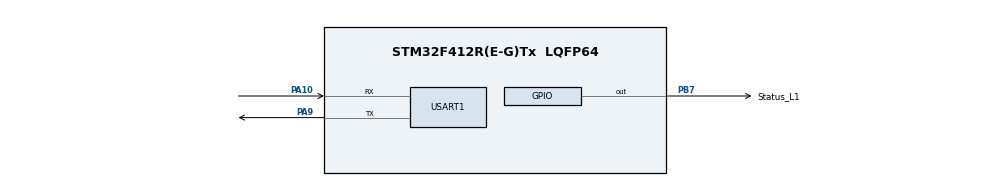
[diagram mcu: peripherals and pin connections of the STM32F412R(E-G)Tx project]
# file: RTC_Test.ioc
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Mcu.Family=STM32F4
Mcu.Name=STM32F412R(E-G)Tx
Mcu.Package=LQFP64
NVIC.PriorityGroup=NVIC_PRIORITYGROUP_4
PA10.Mode=Asynchronous
PA10.Signal=USART1_RX
PA13.Mode=Serial_Wire
PA13.Signal=SYS_JTMS-SWDIO
PA14.Mode=Serial_Wire
PA14.Signal=SYS_JTCK-SWCLK
PA9.Mode=Asynchronous
PA9.Signal=USART1_TX
PB7.GPIO_Label=Status_L1
PB7.Signal=GPIO_Output
PC14-OSC32_IN.Mode=LSE-External-Oscillator
PC14-OSC32_IN.Signal=RCC_OSC32_IN
PC15-OSC32_OUT.Mode=LSE-External-Oscillator
PC15-OSC32_OUT.Signal=RCC_OSC32_OUT
PH0\ -\ OSC_IN.Mode=HSE-External-Oscillator
PH0\ -\ OSC_IN.Signal=RCC_OSC_IN
PH1\ -\ OSC_OUT.Mode=HSE-External-Oscillator
PH1\ -\ OSC_OUT.Signal=RCC_OSC_OUT
ProjectManager.HeapSize=0x200
ProjectManager.StackSize=0x400
ProjectManager.TargetToolchain=STM32CubeIDE
RCC.CortexFreq_Value=16000000
RCC.HSE_VALUE=16000000
RCC.PLLSourceVirtual=RCC_PLLSOURCE_HSE
RCC.RCC_RTC_Clock_Source=RCC_RTCCLKSOURCE_LSE
RCC.SYSCLKSource=RCC_SYSCLKSOURCE_HSE
RCC.USBFreq_Value=96000000
RCC.VCOOutputFreq_Value=192000000
USART1.VirtualMode=VM_ASYNC
VP_RTC_VS_RTC_Activate.Mode=RTC_Enabled
board=custom

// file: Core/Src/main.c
/* USER CODE BEGIN Header */
/**
  ******************************************************************************
  * @file           : main.c
  * @brief          : Main program body
  ******************************************************************************
  * @attention
  *
  * Copyright (c) 2023 STMicroelectronics.
  * All rights reserved.
  *
  * This software is licensed under terms that can be found in the LICENSE file
  * in the root directory of this software component.
  * If no LICENSE file comes with this software, it is provided AS-IS.
  *
  ******************************************************************************
  */
/* USER CODE END Header */
#include "main.h"

/* USER CODE BEGIN Includes */
#include <string.h>
/* USER CODE END Includes */

RTC_HandleTypeDef hrtc;

UART_HandleTypeDef huart1;

void SystemClock_Config(void);
static void MX_GPIO_Init(void);
static void MX_RTC_Init(void);
static void MX_USART1_UART_Init(void);

/* USER CODE BEGIN 0 */

RTC_TimeTypeDef RTC_Time;
RTC_DateTypeDef RTC_Date;
/* USER CODE END 0 */

int main(void)
{

  /* MCU Configuration--------------------------------------------------------*/

  /* Reset of all peripherals, Initializes the Flash interface and the Systick. */
  HAL_Init();

  /* Configure the system clock */
  SystemClock_Config();

  /* Initialize all configured peripherals */
  MX_GPIO_Init();
  MX_RTC_Init();
  MX_USART1_UART_Init();
  /* USER CODE BEGIN 2 */
  HAL_RTC_Init(&hrtc);
  char DTString[1024];
  /* USER CODE END 2 */

  /* Infinite loop */
  while (1)
  {
	  HAL_RTC_GetTime(&hrtc, &RTC_Time, RTC_FORMAT_BIN);
	  HAL_RTC_GetDate(&hrtc, &RTC_Date, RTC_FORMAT_BIN);

	  sprintf(DTString,"Date: %02d.%02d.%02d  Time: %02d.%02d.%02d\n",RTC_Date.Date,RTC_Date.Month,RTC_Date.Year,RTC_Time.Hours,RTC_Time.Minutes,RTC_Time.Seconds);

	  HAL_GPIO_TogglePin(Status_L1_GPIO_Port,Status_L1_Pin);
	  HAL_UART_Transmit(&huart1, (uint8_t *)DTString, strlen(DTString), 3000);
	  HAL_Delay(1000);
  }
}

void SystemClock_Config(void)
{
  RCC_OscInitTypeDef RCC_OscInitStruct = {0};
  RCC_ClkInitTypeDef RCC_ClkInitStruct = {0};

  /** Configure the main internal regulator output voltage
  */
  __HAL_RCC_PWR_CLK_ENABLE();
  __HAL_PWR_VOLTAGESCALING_CONFIG(PWR_REGULATOR_VOLTAGE_SCALE1);

  /** Initializes the RCC Oscillators according to the specified parameters
  * in the RCC_OscInitTypeDef structure.
  */
  RCC_OscInitStruct.OscillatorType = RCC_OSCILLATORTYPE_HSE|RCC_OSCILLATORTYPE_LSE;
  RCC_OscInitStruct.HSEState = RCC_HSE_ON;
  RCC_OscInitStruct.LSEState = RCC_LSE_ON;
  RCC_OscInitStruct.PLL.PLLState = RCC_PLL_NONE;
  if (HAL_RCC_OscConfig(&RCC_OscInitStruct) != HAL_OK)
  {
    Error_Handler();
  }

  /** Initializes the CPU, AHB and APB buses clocks
  */
  RCC_ClkInitStruct.ClockType = RCC_CLOCKTYPE_HCLK|RCC_CLOCKTYPE_SYSCLK
                              |RCC_CLOCKTYPE_PCLK1|RCC_CLOCKTYPE_PCLK2;
  RCC_ClkInitStruct.SYSCLKSource = RCC_SYSCLKSOURCE_HSE;
  RCC_ClkInitStruct.AHBCLKDivider = RCC_SYSCLK_DIV1;
  RCC_ClkInitStruct.APB1CLKDivider = RCC_HCLK_DIV1;
  RCC_ClkInitStruct.APB2CLKDivider = RCC_HCLK_DIV1;

  if (HAL_RCC_ClockConfig(&RCC_ClkInitStruct, FLASH_LATENCY_0) != HAL_OK)
  {
    Error_Handler();
  }
}

static void MX_RTC_Init(void)
{

  /** Initialize RTC Only
  */
  hrtc.Instance = RTC;
  hrtc.Init.HourFormat = RTC_HOURFORMAT_24;
  hrtc.Init.AsynchPrediv = 127;
  hrtc.Init.SynchPrediv = 255;
  hrtc.Init.OutPut = RTC_OUTPUT_DISABLE;
  hrtc.Init.OutPutPolarity = RTC_OUTPUT_POLARITY_HIGH;
  hrtc.Init.OutPutType = RTC_OUTPUT_TYPE_OPENDRAIN;
  if (HAL_RTC_Init(&hrtc) != HAL_OK)
  {
    Error_Handler();
  }

}

static void MX_USART1_UART_Init(void)
{

  huart1.Instance = USART1;
  huart1.Init.BaudRate = 115200;
  huart1.Init.WordLength = UART_WORDLENGTH_8B;
  huart1.Init.StopBits = UART_STOPBITS_1;
  huart1.Init.Parity = UART_PARITY_NONE;
  huart1.Init.Mode = UART_MODE_TX_RX;
  huart1.Init.HwFlowCtl = UART_HWCONTROL_NONE;
  huart1.Init.OverSampling = UART_OVERSAMPLING_16;
  if (HAL_UART_Init(&huart1) != HAL_OK)
  {
    Error_Handler();
  }

}

static void MX_GPIO_Init(void)
{
  GPIO_InitTypeDef GPIO_InitStruct = {0};

  /* GPIO Ports Clock Enable */
  __HAL_RCC_GPIOC_CLK_ENABLE();
  __HAL_RCC_GPIOH_CLK_ENABLE();
  __HAL_RCC_GPIOA_CLK_ENABLE();
  __HAL_RCC_GPIOB_CLK_ENABLE();

  /*Configure GPIO pin Output Level */
  HAL_GPIO_WritePin(Status_L1_GPIO_Port, Status_L1_Pin, GPIO_PIN_RESET);

  /*Configure GPIO pin : Status_L1_Pin */
  GPIO_InitStruct.Pin = Status_L1_Pin;
  GPIO_InitStruct.Mode = GPIO_MODE_OUTPUT_PP;
  GPIO_InitStruct.Pull = GPIO_NOPULL;
  GPIO_InitStruct.Speed = GPIO_SPEED_FREQ_LOW;
  HAL_GPIO_Init(Status_L1_GPIO_Port, &GPIO_InitStruct);

}

void Error_Handler(void)
{
  __disable_irq();
  while (1)
  {
  }
}
